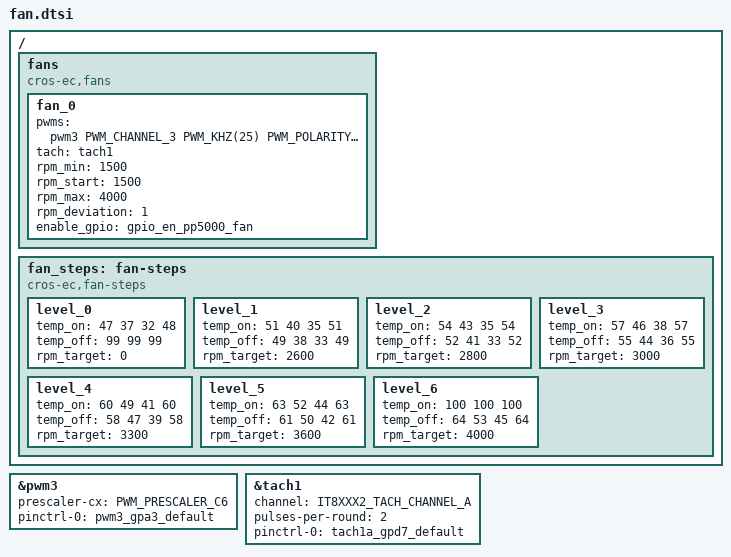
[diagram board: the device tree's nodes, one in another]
/* Copyright 2024 The ChromiumOS Authors
 * Use of this source code is governed by a BSD-style license that can be
 * found in the LICENSE file.
 */

/ {
	fans {
		compatible = "cros-ec,fans";
		fan_0 {
			pwms = <&pwm3 PWM_CHANNEL_3 PWM_KHZ(25) PWM_POLARITY_NORMAL>;
			tach = <&tach1>;
			rpm_min = <1500>;
			rpm_start = <1500>;
			rpm_max = <4000>;
			rpm_deviation = <1>;
			enable_gpio = <&gpio_en_pp5000_fan>;
		};
	};

	fan_steps: fan-steps {			
		compatible = "cros-ec,fan-steps";		
		level_0 {		
			temp_on = <47 37 32 48>;	
			temp_off = <99 99 99>;	
			rpm_target = <0>;	
		};		
		level_1 {		
			temp_on = <51 40 35 51>;	
			temp_off = <49 38 33 49>;	
			rpm_target = <2600>;	
		};		
		level_2 {		
			temp_on = <54 43 35 54>;	
			temp_off = <52 41 33 52>;	
			rpm_target = <2800>;	
		};		
		level_3 {		
			temp_on = <57 46 38 57>;	
			temp_off = <55 44 36 55>;	
			rpm_target = <3000>;	
		};		
		level_4 {		
			temp_on = <60 49 41 60>;	
			temp_off = <58 47 39 58>;	
			rpm_target = <3300>;	
		};		
		level_5 {		
			temp_on = <63 52 44 63>;	
			temp_off = <61 50 42 61>;	
			rpm_target = <3600>;	
		};		
		level_6 {		
			temp_on = <100 100 100>;	
			temp_off = <64 53 45 64>;	
			rpm_target = <4000>;	
		};		
	};			
 };

/* pwm for fan */
&pwm3 {
	status = "okay";
	prescaler-cx = <PWM_PRESCALER_C6>;
	pinctrl-0 = <&pwm3_gpa3_default>;
	pinctrl-names = "default";
};

/* fan tachometer sensor */
&tach1 {
	status = "okay";
	channel = <IT8XXX2_TACH_CHANNEL_A>;
	pulses-per-round = <2>;
	pinctrl-0 = <&tach1a_gpd7_default>;
	pinctrl-names = "default";
};
